# Z32F3841 register map
Vendor: Zilog, Inc; File version: 1.0.1
CPU: CM3 r2p0, little endian, no MPU, no FPU, 3 interrupt priority bits
Registers are 32-bit, read-write, reset 0x0 unless marked. A register's access mark holds for its fields unless they carry their own. Offsets are from the block's base; [hi:lo] are bit positions; {n}, {i} and the like mark numbered series.

## T0 — 16-BIT TIMER
Base 0x40003000
Same registers: T{n} {0x40003000+0x20*n} (n=1..9)
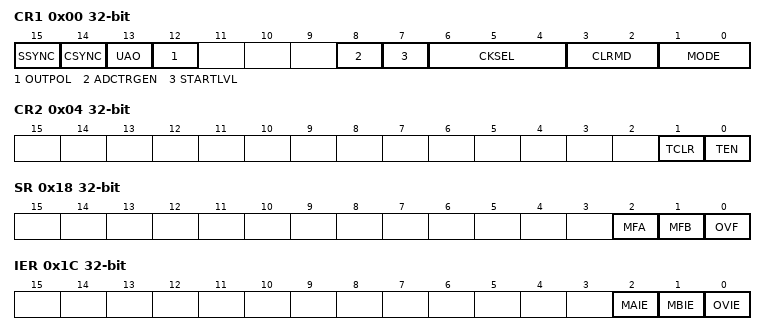
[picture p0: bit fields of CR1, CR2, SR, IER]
0x00 CR1 — Timer n Control Register 1
  [15] SSYNC — Synchronized start counter with other synchronized timers
  [14] CSYNC — Synchronized clear counter with other synchronized timers
  [13] UAO — Select GRA, GRB update mode
  [12] OUTPOL — Timer ouput Polarity
  [8] ADCTRGEN
  [7] STARTLVL — Timer output polarity control
  [6:4] CKSEL — counter clock source select
  [3:2] CLRMD — clear select when capture mode
  [1:0] MODE — Timer operatin mode control
0x04 CR2 — Timer n Control Register 2
  [1] TCLR — Timer register clear
  [0] TEN — Timer enable bit
0x08 PRS — Timer n Prescaler Register
  [9:0] PRS — Prescaler value of count clock
0x0C GRA — Timer n General Register A
  [15:0] GRA
0x10 GRB — Timer n General Register B
  [15:0] GRB
0x14 CNT — Timer n Count Register
  [15:0] CNT
0x18 SR — Timer n Status Register
  [2] MFA — Match register A Flag
  [1] MFB — MATCH register B flag
  [0] OVF — counter overflow falg
0x1C IER — Timer n Interrupt Enable Register
  [2] MAIE — GRA Match interrupt enablee
  [1] MBIE — GRB Match interrupt enable
  [0] OVIE — Counter overflow interrupt enable

## FRT — 32bit Free Run Timer
Base 0x40000600
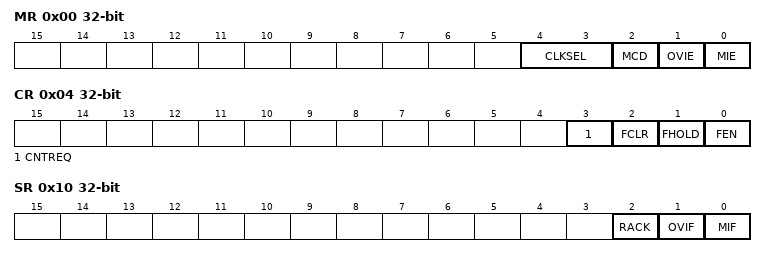
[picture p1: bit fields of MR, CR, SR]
0x00 MR — Free Run Timer Mode Register
  [4:3] CLKSEL — FRT Counter clock source
  [2] MCD — Counter Match clear Disable flag
  [1] OVIE — Overflow Interrupt Enable
  [0] MIE — MatchInterrupt Enable
0x04 CR — Free Run Timer Control Register
  [3] CNTREQ — FRT Counter Read Request bitr
  [2] FCLR — Counter Register Clear
  [1] FHOLD — Counter Register Hold
  [0] FEN — FRT Enable
0x08 PER — Free Run Timer Period Match Register
  [31:0] DATA — FRT Match Data
0x0C CNT ro — Free Run Timer Counter Register
0x10 SR — Free Run Timer Status Register
  [2] RACK — Read Counter Acknowledge bit
  [1] OVIF — Overflow Interrupt flag
  [0] MIF — Match Interrupt flag

## U0 — UNIVERSAL ASYNCHRONOUS RECEIVER/TRANSMITTER
Base 0x40008000
Same registers: U1 0x40008100, U2 0x40008200, U3 0x40008300
0x00 RBR ro — Receive Buffer Register
  [7:0] RBR — recevied/transmit data
0x00 THR wo — Transmit Data Hold Register
  [7:0] THR — recevied/transmit data
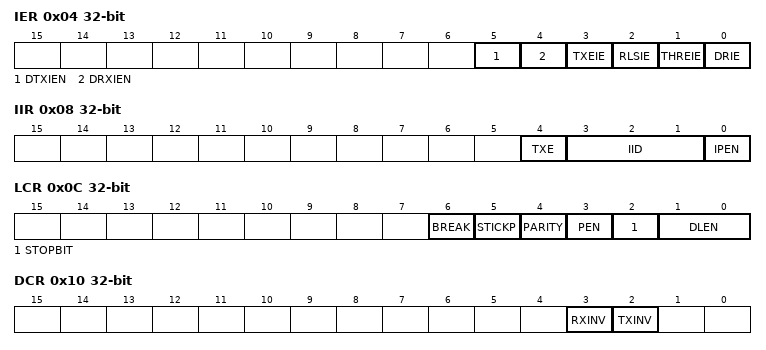
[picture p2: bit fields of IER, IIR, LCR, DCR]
0x04 IER — UART Interrupt Enable Register
  [5] DTXIEN — DMA transmit done interrupt enable
  [4] DRXIEN — DMA Receiver line status interrupt enable
  [3] TXEIE — End-of-transmit interrupt enable
  [2] RLSIE — receiver line status interrupt enable
  [1] THREIE — Transmit holding register empty interrupt enable
  [0] DRIE — Data receive interrupt enable
0x08 IIR ro — UART Interrupt ID Register
  [4] TXE — Interrupt Status
  [3:1] IID — Interrupt source ID
  [0] IPEN — Interrupt pending bit
0x0C LCR — UART Line Control Register
  [6] BREAK
  [5] STICKP — STICK
  [4] PARITY
  [3] PEN — parity bit transfer enable
  [2] STOPBIT
  [1:0] DLEN — Data length in one transfer word
0x10 DCR — UART Data Control Register
  [3] RXINV — Rx Data Inversion selection
  [2] TXINV — TX Data Inversion selection
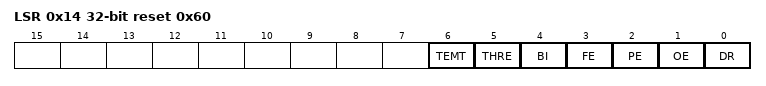
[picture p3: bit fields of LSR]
0x14 LSR reset 0x60 — UART Line Status Register
  [6] TEMT ro — Transmit empty
  [5] THRE ro — Transmit holding register empty
  [4] BI ro — break condition indication bit
  [3] FE ro — frame error
  [2] PE ro — parity error
  [1] OE ro — overrun error
  [0] DR ro — Data recevied
0x20 BDR — Baud rate Divisor Latch Register
  [15:0] BDR — baudrate setting
0x24 BFR — Baud rate Fraction Counter Register
  [7:0] BFR — Fraction counter value
0x30 IDTR — Inter-frame Delay Time Register
  [2:0] WAITVAL — wait time is decided by this value

## SP0 — SERIAL PERIPHERAL INTERFACE
Base 0x40009000
Same registers: SP1 0x40009100
0x00 RDR ro (reset mask 0xFFFF) — SPI n Receive Data Register
  [16:0] RDR — Data
0x00 TDR wo (reset mask 0xFFFF) — SPI n Transmit Data Register
  [16:0] TDR — Data
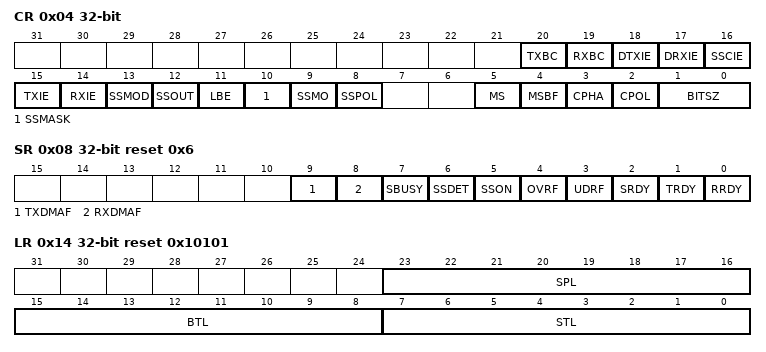
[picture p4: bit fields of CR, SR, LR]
0x04 CR — SPI n Control Register
  [20] TXBC — TX Buffer clear bitr
  [19] RXBC — Recieve buffer clear enable
  [18] DTXIE — DMA TX Done Interrupt enable bit
  [17] DRXIE — DMA Rx Deone Interrupt enable bit
  [16] SSCIE — SSn Edge Chagne Interrupt enable bit
  [15] TXIE — Transmit interrupt enable bit
  [14] RXIE — Receive interrupt enable bit
  [13] SSMOD — SS Auto/Manual Output select bit
  [12] SSOUT — SS output signal select bit
  [11] LBE — Loop-back mode select bit in master mode
  [10] SSMASK — SS Signal masking bit in slave mode
  [9] SSMO — SS output signal select bit
  [8] SSPOL — SS Signal polarity select bit
  [5] MS — master/slaver select bit
  [4] MSBF — MSB/LSB transmit select bit
  [3] CPHA — SPI clock phase bit
  [2] CPOL — SPI clock polarity bit
  [1:0] BITSZ — Transmit/receive Data bits select bit
0x08 SR reset 0x6 — SPI n Status Register
  [9] TXDMAF — DMA transmit Operation complete flag
  [8] RXDMAF — DMA receive Operation complete flag
  [7] SBUSY ro — Transmit/Receive Operation flag
  [6] SSDET — The rising edge of SS detect flag
  [5] SSON — SS signal status flag
  [4] OVRF — receive overrun error flag
  [3] UDRF — transmit underrun error flag
  [2] SRDY ro — Shift register ready flag
  [1] TRDY ro — Transmit buffer empty flag
  [0] RRDY ro — receive buffer ready flag
0x0C BR reset 0xFF — SPI n Baud Rate Register
  [15:0] BR — buadrate
0x10 EN — SPI n Enable register
  [0] ENABLE — SPI ENABLE bit
0x14 LR reset 0x10101 — SPI n delay Length Register
  [23:16] SPL — Stop delay length
  [15:8] BTL — Burst delay length
  [7:0] STL — Start delay length

## IC0 — I2C Interface
Base 0x4000A000
Same registers: IC1 0x4000A100
0x00 DR — I2C Data Register
  [7:0] DR — Data
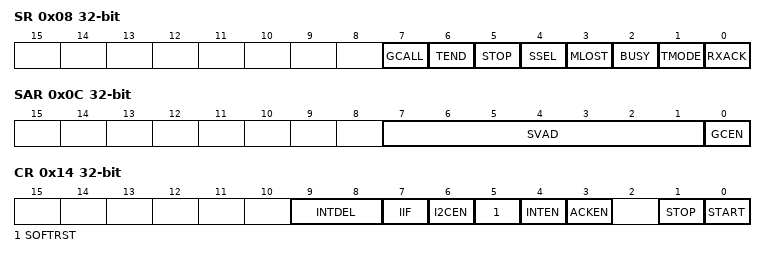
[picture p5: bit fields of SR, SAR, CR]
0x08 SR — Status register
  [7] GCALL — General call flag
  [6] TEND — 1 byte transmission complete flag
  [5] STOP — Stop Flag
  [4] SSEL — slave flag (start condition received)
  [3] MLOST — Mastership lost flag
  [2] BUSY — busy flag
  [1] TMODE — Transmit/reciever mode flag
  [0] RXACK — RX ack flag
0x0C SAR — I2C Slave Address Register
  [7:1] SVAD — 7 bits slave address
  [0] GCEN — general call enable bit
0x14 CR (reset mask 0xFF) — I2C Control Register
  [9:8] INTDEL — Interval delay between Addr and Data
  [7] IIF — Interrupt Flag
  [6] I2CEN — I2C Enable Bit
  [5] SOFTRST — Soft reset enable bit
  [4] INTEN — Interrupt enable bit
  [3] ACKEN — ACK enabit bit in receiver mode
  [1] STOP — Stop enable bit
  [0] START — transmission start bit in master mode
0x18 SCLL reset 0xFFFF — I2C SCL LOW duration Register
  [15:0] SCLL — SCL Low duration value
0x1C SCLH reset 0xFFFF — I2C SCL HIGH duration Register
  [15:0] SCLH — SCL High duration value
0x20 SDH reset 0x7F — SDA Hold Register
  [14:0] SDH — SDA Hold time

## AD0 — 12-BIT A/D CONVERTER
Base 0x4000B000
Same registers: AD1 0x4000B100
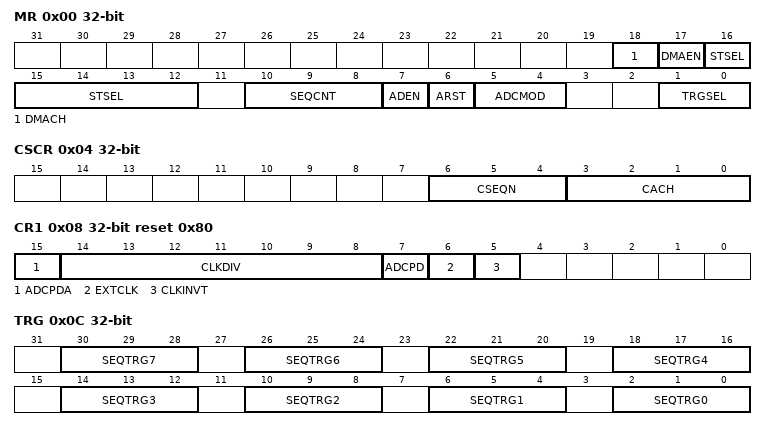
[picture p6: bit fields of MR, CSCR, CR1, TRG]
0x00 MR — ADCn Mode Register
  [18] DMACH — DMA Channel option
  [17] DMAEN — DMA Enable
  [16:12] STSEL — Sampling Time Selection
  [10:8] SEQCNT — Sequence count
  [7] ADEN — ADC Enable
  [6] ARST — Stop at end of sequence
  [5:4] ADCMOD — ADC convert mode
  [1:0] TRGSEL — ADC Trigger source sel
0x04 CSCR — ADCn Current Sequence/Channel Register
  [6:4] CSEQN — Current Sequence Number
  [3:0] CACH ro — Current Active Channel
0x08 CR1 reset 0x80 — ADCn Clock Control Register
  [15] ADCPDA — ADC R-ADC disable to save power
  [14:8] CLKDIV — ADC clock divider
  [7] ADCPD — ADC Power down
  [6] EXTCLK — ADCuse external clock
  [5] CLKINVT — divided clock inversion
0x0C TRG — ADC Trigger Selection Register
  [4n+2:4n] SEQTRG{n} (n=0..7) — Sequence Trigger {n}
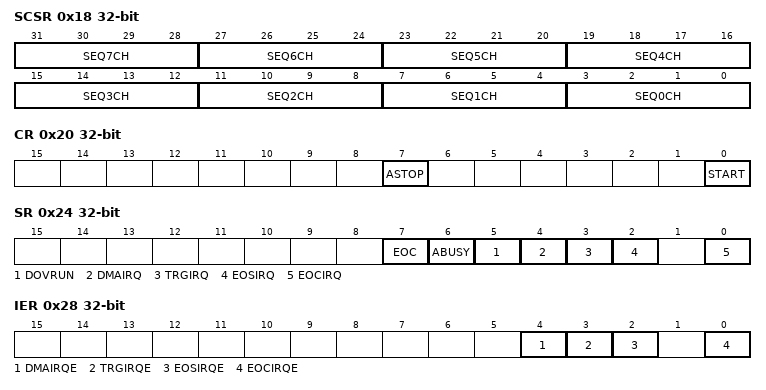
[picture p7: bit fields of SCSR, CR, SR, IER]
0x18 SCSR — ADC Sequence Channel select
  [4n+3:4n] SEQ{n}CH (n=3..7) — {n+1}th sequence coversion channel selection
  [11:8] SEQ2CH — 3rd sequence coversion channel selection
  [7:4] SEQ1CH — 2nd sequence coversion channel selection
  [3:0] SEQ0CH — 1st sequence coversion channel selection
0x20 CR — ADCn Control Register
  [7] ASTOP wo — ADC Stop
  [0] START — ADC conversion start
0x24 SR — ADC Status Register
  [7] EOC ro — End of Conversion Flag
  [6] ABUSY ro — ADC conversion busy flag
  [5] DOVRUN ro — DMA overrun flag
  [4] DMAIRQ — DMA received/transfer is done
  [3] TRGIRQ — ADC Trigger interrupt flag
  [2] EOSIRQ — End of Sequence interrupt flag
  [0] EOCIRQ — Each conversion in sequence interrupt flag
0x28 IER — Interrupt Enable Register
  [4] DMAIRQE — DMA done interrupt enable
  [3] TRGIRQE — ADC Trigger conversion intterupt enable
  [2] EOSIRQE — ADC End of Sequence interrupt enable
  [0] EOCIRQE — Conversion Complete interrupt enable
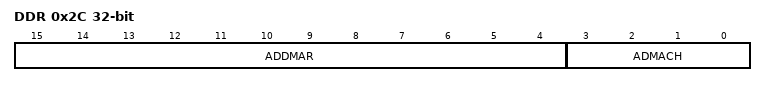
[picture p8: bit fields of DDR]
0x2C DDR ro — ADC DMA Data Register
  [15:4] ADDMAR — ADC conversion result data
  [3:0] ADMACH — ADC data channel indicator
{0x30+4i} DR{i} ro (i=0..7) — ADC Sequence Data Register {i+1}
  [15:4] ADCDATA — ADC Sequence Data
